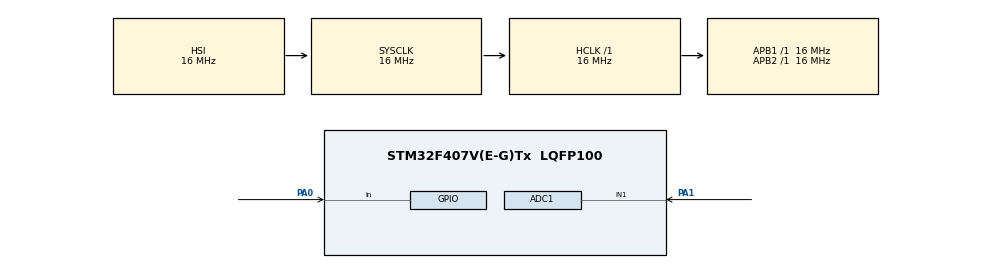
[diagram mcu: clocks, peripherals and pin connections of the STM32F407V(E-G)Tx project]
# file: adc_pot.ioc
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Mcu.Family=STM32F4
RCC.VCOOutputFreq_Value=192000000
RCC.APB2Freq_Value=16000000
RCC.CortexFreq_Value=16000000
ADC1.Rank-0\#ChannelRegularConversion=1
Mcu.Name=STM32F407V(E-G)Tx
ADC1.SamplingTime-0\#ChannelRegularConversion=ADC_SAMPLETIME_144CYCLES
RCC.SYSCLKFreq_VALUE=16000000
Mcu.Package=LQFP100
ADC1.master=1
ProjectManager.StackSize=0x400
PA0-WKUP.Signal=GPIO_Input
NVIC.ADC_IRQn=true\:0\:0\:false\:false\:true\:true\:true
ProjectManager.HeapSize=0x200
ProjectManager.TargetToolchain=STM32CubeIDE
RCC.HSI_VALUE=16000000
NVIC.PriorityGroup=NVIC_PRIORITYGROUP_4
ADC1.NbrOfConversionFlag=1
SH.ADCx_IN1.0=ADC1_IN1,IN1
ADC1.Resolution=ADC_RESOLUTION_6B
RCC.APB1Freq_Value=16000000
RCC.LSE_VALUE=32768
PA1.Signal=ADCx_IN1
RCC.AHBFreq_Value=16000000
ADC1.Channel-0\#ChannelRegularConversion=ADC_CHANNEL_1
RCC.HSE_VALUE=25000000
board=custom

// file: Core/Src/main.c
/* USER CODE BEGIN Header */
/**
  ******************************************************************************
  * @file           : main.c
  * @brief          : Main program body
  ******************************************************************************
  * @attention
  *
  * <h2><center>&copy; Copyright (c) 2021 STMicroelectronics.
  * All rights reserved.</center></h2>
  *
  * This software component is licensed by ST under BSD 3-Clause license,
  * the "License"; You may not use this file except in compliance with the
  * License. You may obtain a copy of the License at:
  *                        opensource.org/licenses/BSD-3-Clause
  *
  ******************************************************************************
  */
/* USER CODE END Header */
#include "main.h"

ADC_HandleTypeDef hadc1;

void SystemClock_Config(void);
static void MX_GPIO_Init(void);
static void MX_ADC1_Init(void);

/* USER CODE BEGIN 0 */
uint16_t adc_degeri;
/* USER CODE END 0 */

int main(void)
{

  /* MCU Configuration--------------------------------------------------------*/

  /* Reset of all peripherals, Initializes the Flash interface and the Systick. */
  HAL_Init();

  /* Configure the system clock */
  SystemClock_Config();

  /* Initialize all configured peripherals */
  MX_GPIO_Init();
  MX_ADC1_Init();

  /* Infinite loop */
  while (1)
  {

    /* USER CODE BEGIN 3 */
	  HAL_ADC_Start(&hadc1); // ADC1'i başlattık.
	  HAL_Delay(100);
	  adc_degeri = HAL_ADC_GetValue(&hadc1);//adc1'den gelen değeri adc_degeri degiskenimize atadık
  }
  /* USER CODE END 3 */
}

void SystemClock_Config(void)
{
  RCC_OscInitTypeDef RCC_OscInitStruct = {0};
  RCC_ClkInitTypeDef RCC_ClkInitStruct = {0};

  /** Configure the main internal regulator output voltage
  */
  __HAL_RCC_PWR_CLK_ENABLE();
  __HAL_PWR_VOLTAGESCALING_CONFIG(PWR_REGULATOR_VOLTAGE_SCALE1);
  /** Initializes the RCC Oscillators according to the specified parameters
  * in the RCC_OscInitTypeDef structure.
  */
  RCC_OscInitStruct.OscillatorType = RCC_OSCILLATORTYPE_HSI;
  RCC_OscInitStruct.HSIState = RCC_HSI_ON;
  RCC_OscInitStruct.HSICalibrationValue = RCC_HSICALIBRATION_DEFAULT;
  RCC_OscInitStruct.PLL.PLLState = RCC_PLL_NONE;
  if (HAL_RCC_OscConfig(&RCC_OscInitStruct) != HAL_OK)
  {
    Error_Handler();
  }
  /** Initializes the CPU, AHB and APB buses clocks
  */
  RCC_ClkInitStruct.ClockType = RCC_CLOCKTYPE_HCLK|RCC_CLOCKTYPE_SYSCLK
                              |RCC_CLOCKTYPE_PCLK1|RCC_CLOCKTYPE_PCLK2;
  RCC_ClkInitStruct.SYSCLKSource = RCC_SYSCLKSOURCE_HSI;
  RCC_ClkInitStruct.AHBCLKDivider = RCC_SYSCLK_DIV1;
  RCC_ClkInitStruct.APB1CLKDivider = RCC_HCLK_DIV1;
  RCC_ClkInitStruct.APB2CLKDivider = RCC_HCLK_DIV1;

  if (HAL_RCC_ClockConfig(&RCC_ClkInitStruct, FLASH_LATENCY_0) != HAL_OK)
  {
    Error_Handler();
  }
}

static void MX_ADC1_Init(void)
{

  ADC_ChannelConfTypeDef sConfig = {0};

  /** Configure the global features of the ADC (Clock, Resolution, Data Alignment and number of conversion)
  */
  hadc1.Instance = ADC1;
  hadc1.Init.ClockPrescaler = ADC_CLOCK_SYNC_PCLK_DIV2;
  hadc1.Init.Resolution = ADC_RESOLUTION_6B;
  hadc1.Init.ScanConvMode = DISABLE;
  hadc1.Init.ContinuousConvMode = DISABLE;
  hadc1.Init.DiscontinuousConvMode = DISABLE;
  hadc1.Init.ExternalTrigConvEdge = ADC_EXTERNALTRIGCONVEDGE_NONE;
  hadc1.Init.ExternalTrigConv = ADC_SOFTWARE_START;
  hadc1.Init.DataAlign = ADC_DATAALIGN_RIGHT;
  hadc1.Init.NbrOfConversion = 1;
  hadc1.Init.DMAContinuousRequests = DISABLE;
  hadc1.Init.EOCSelection = ADC_EOC_SINGLE_CONV;
  if (HAL_ADC_Init(&hadc1) != HAL_OK)
  {
    Error_Handler();
  }
  /** Configure for the selected ADC regular channel its corresponding rank in the sequencer and its sample time.
  */
  sConfig.Channel = ADC_CHANNEL_1;
  sConfig.Rank = 1;
  sConfig.SamplingTime = ADC_SAMPLETIME_144CYCLES;
  if (HAL_ADC_ConfigChannel(&hadc1, &sConfig) != HAL_OK)
  {
    Error_Handler();
  }

}

static void MX_GPIO_Init(void)
{
  GPIO_InitTypeDef GPIO_InitStruct = {0};

  /* GPIO Ports Clock Enable */
  __HAL_RCC_GPIOA_CLK_ENABLE();

  /*Configure GPIO pin : PA0 */
  GPIO_InitStruct.Pin = GPIO_PIN_0;
  GPIO_InitStruct.Mode = GPIO_MODE_INPUT;
  GPIO_InitStruct.Pull = GPIO_NOPULL;
  HAL_GPIO_Init(GPIOA, &GPIO_InitStruct);

}

void Error_Handler(void)
{
  __disable_irq();
  while (1)
  {
  }
}

/************************ (C) COPYRIGHT STMicroelectronics *****END OF FILE****/
